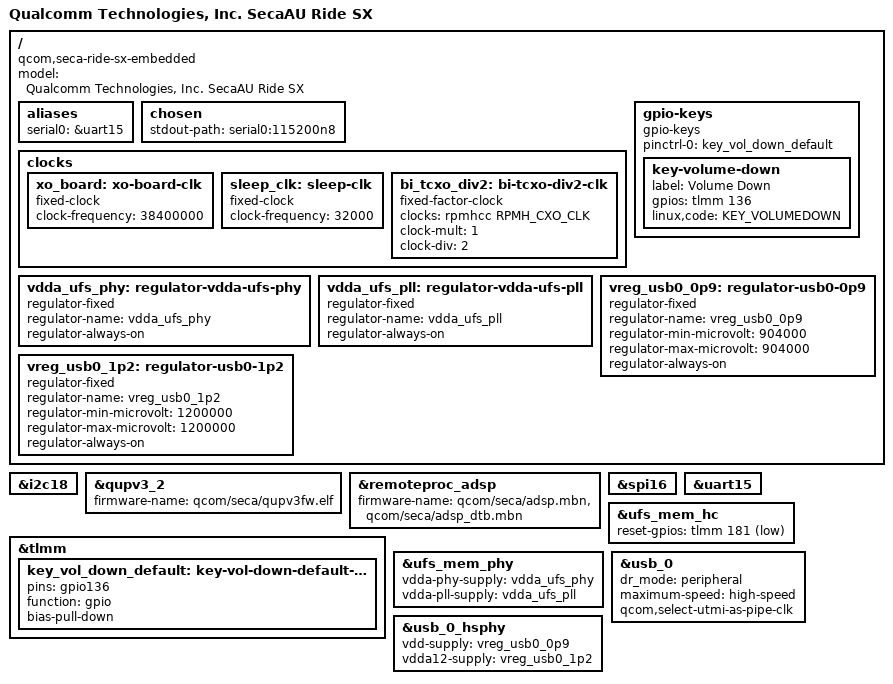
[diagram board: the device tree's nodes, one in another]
// SPDX-License-Identifier: BSD-3-Clause
/*
 * Copyright (c) Qualcomm Technologies, Inc. and/or its subsidiaries.
 */

/dts-v1/;

#include <dt-bindings/gpio/gpio.h>
#include <dt-bindings/input/linux-event-codes.h>
#include "seca-embedded.dtsi"

/ {
	model = "Qualcomm Technologies, Inc. SecaAU Ride SX";
	compatible = "qcom,seca-ride-sx-embedded", "qcom,seca";

	aliases {
		serial0 = &uart15;
	};

	chosen {
		stdout-path = "serial0:115200n8";
	};

	clocks {
		xo_board: xo-board-clk {
			compatible = "fixed-clock";
			clock-frequency = <38400000>;
			#clock-cells = <0>;
		};

		sleep_clk: sleep-clk {
			compatible = "fixed-clock";
			clock-frequency = <32000>;
			#clock-cells = <0>;
		};

		bi_tcxo_div2: bi-tcxo-div2-clk {
			compatible = "fixed-factor-clock";
			#clock-cells = <0>;
			clocks = <&rpmhcc RPMH_CXO_CLK>;
			clock-mult = <1>;
			clock-div = <2>;
		};
	};

	gpio-keys {
		compatible = "gpio-keys";

		pinctrl-0 = <&key_vol_down_default>;
		pinctrl-names = "default";

		key-volume-down {
			label = "Volume Down";
			gpios = <&tlmm 136 GPIO_ACTIVE_HIGH>;
			linux,code = <KEY_VOLUMEDOWN>;
		};
	};

	/*
	 * The boot firmware owns the UFS PHY rails: cmd-db offers no PMIC
	 * LDO resources to the application processor on this platform.
	 */
	vdda_ufs_phy: regulator-vdda-ufs-phy {
		compatible = "regulator-fixed";
		regulator-name = "vdda_ufs_phy";
		regulator-always-on;
	};

	vdda_ufs_pll: regulator-vdda-ufs-pll {
		compatible = "regulator-fixed";
		regulator-name = "vdda_ufs_pll";
		regulator-always-on;
	};

	/* The boot firmware owns the eUSB2 PHY rails as well. */
	vreg_usb0_0p9: regulator-usb0-0p9 {
		compatible = "regulator-fixed";
		regulator-name = "vreg_usb0_0p9";
		regulator-min-microvolt = <904000>;
		regulator-max-microvolt = <904000>;
		regulator-always-on;
	};

	vreg_usb0_1p2: regulator-usb0-1p2 {
		compatible = "regulator-fixed";
		regulator-name = "vreg_usb0_1p2";
		regulator-min-microvolt = <1200000>;
		regulator-max-microvolt = <1200000>;
		regulator-always-on;
	};
};

&i2c18 {
	status = "okay";
};

&qupv3_2 {
	firmware-name = "qcom/seca/qupv3fw.elf";
};

&remoteproc_adsp {
	firmware-name = "qcom/seca/adsp.mbn",
			"qcom/seca/adsp_dtb.mbn";

	status = "okay";
};

&spi16 {
	status = "okay";
};

&tlmm {
	key_vol_down_default: key-vol-down-default-state {
		pins = "gpio136";
		function = "gpio";
		bias-pull-down;
	};
};

&uart15 {
	status = "okay";
};

&ufs_mem_hc {
	reset-gpios = <&tlmm 181 GPIO_ACTIVE_LOW>;

	status = "okay";
};

&ufs_mem_phy {
	vdda-phy-supply = <&vdda_ufs_phy>;
	vdda-pll-supply = <&vdda_ufs_pll>;

	status = "okay";
};

&usb_0 {
	dr_mode = "peripheral";
	maximum-speed = "high-speed";
	qcom,select-utmi-as-pipe-clk;

	status = "okay";
};

&usb_0_hsphy {
	vdd-supply = <&vreg_usb0_0p9>;
	vdda12-supply = <&vreg_usb0_1p2>;

	status = "okay";
};
